# MM32F031x8 register map
Vendor: MindMotion Ltd.; Series: MM32F0; File version: 1.4
CPU: CM0 r0p0, little endian, no MPU, no FPU, 3 interrupt priority bits
Registers are 32-bit, read-write, reset 0x0 unless marked. A register's access mark holds for its fields unless they carry their own. Offsets are from the block's base; [hi:lo] are bit positions.

## RCC — Reset and clock control
Base 0x40021000
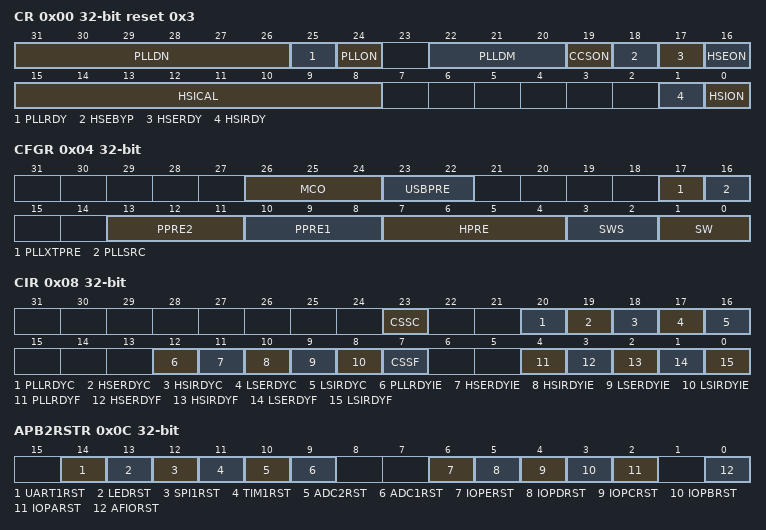
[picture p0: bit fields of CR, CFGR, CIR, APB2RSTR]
0x00 CR reset 0x3
  [31:26] PLLDN — PLL divider factor
  [25] PLLRDY — PLL clock ready flag
  [24] PLLON — PLL enable
  [22:20] PLLDM — PLL divider factor
  [19] CCSON — Clock security system enable
  [18] HSEBYP — External high-speed clock bypass
  [17] HSERDY — External high-speed clock ready flag
  [16] HSEON — External high-speed clock enable
  [15:8] HSICAL — Internal high-speed clock calibration
  [1] HSIRDY — Internal high-speed clock ready flag
  [0] HSION — Internal high-speed clock enable
0x04 CFGR
  [26:24] MCO — Microcontroller clock output
  [23:22] USBPRE — USB prescaler
  [17] PLLXTPRE — HSE divider for PLL entry
  [16] PLLSRC — PLL entry clock source
  [13:11] PPRE2 — APB high-speed prescaler(APB2)
  [10:8] PPRE1 — APB low-speed prescaler(APB1)
  [7:4] HPRE — AHB Prescaler
  [3:2] SWS — System clock switch status
  [1:0] SW — System clock switch
0x08 CIR
  [23] CSSC — Clock security system interrupt clear
  [20] PLLRDYC — PLL ready interrupt clear
  [19] HSERDYC — HSE ready interrupt clear
  [18] HSIRDYC — HSI ready interrupt clear
  [17] LSERDYC — LSE ready interrupt clear
  [16] LSIRDYC — LSI ready interrupt clear
  [12] PLLRDYIE — PLL ready interrupt enable
  [11] HSERDYIE — HSE ready interrupt enable
  [10] HSIRDYIE — HSI ready interrupt enable
  [9] LSERDYIE — LSE ready interrupt enable
  [8] LSIRDYIE — LSI ready interrupt enable
  [7] CSSF — Clock security system interrupt flag
  [4] PLLRDYF — PLL ready interrupt flag
  [3] HSERDYF — HSE ready interrupt flag
  [2] HSIRDYF — HSI ready interrupt flag
  [1] LSERDYF — LSE ready interrupt flag
  [0] LSIRDYF — LSI ready interrupt flag
0x0C APB2RSTR
  [14] UART1RST — UART 1 reset
  [13] LEDRST — LED reset
  [12] SPI1RST — SPI 1 reset
  [11] TIM1RST — TIM1 timer reset
  [10] ADC2RST — ADC2 interface reset
  [9] ADC1RST — ADC1 interface reset
  [6] IOPERST — IO port E reset
  [5] IOPDRST — IO port D reset
  [4] IOPCRST — IO port C reset
  [3] IOPBRST — IO port B reset
  [2] IOPARST — IO port A reset
  [0] AFIORST — Alternate function I/O reset
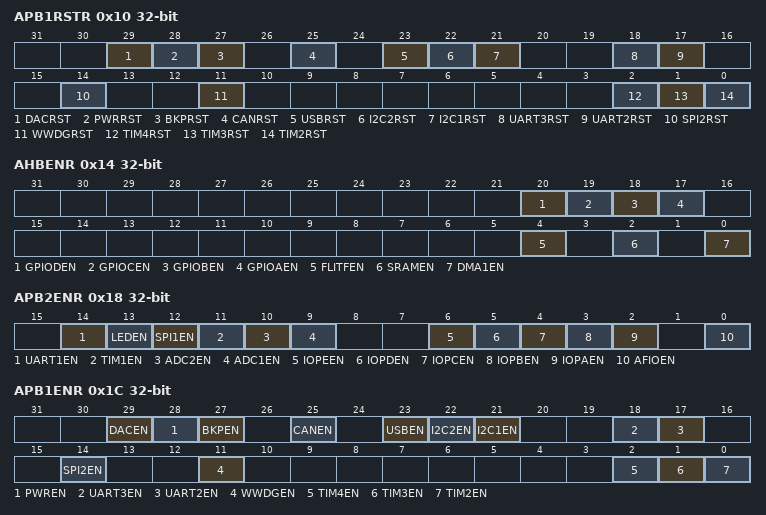
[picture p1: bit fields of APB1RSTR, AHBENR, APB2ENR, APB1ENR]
0x10 APB1RSTR
  [29] DACRST — DAC interface reset
  [28] PWRRST — Power interface reset
  [27] BKPRST — Backup interface reset
  [25] CANRST — CAN reset
  [23] USBRST — USB reset
  [22] I2C2RST — I2C 2 reset
  [21] I2C1RST — I2C 1 reset
  [18] UART3RST — UART 3 reset
  [17] UART2RST — UART 2 reset
  [14] SPI2RST — SPI 2 reset
  [11] WWDGRST — Window watchdog reset
  [2] TIM4RST — Timer 4 reset
  [1] TIM3RST — Timer 3 reset
  [0] TIM2RST — Timer 2 reset
0x14 AHBENR
  [20] GPIODEN — GPIOD clock enable
  [19] GPIOCEN — GPIOC clock enable
  [18] GPIOBEN — GPIOB clock enable
  [17] GPIOAEN — GPIOA clock enable
  [4] FLITFEN — FLITF clock enable
  [2] SRAMEN — SRAM interface clock enable
  [0] DMA1EN — DMA1 clock enable
0x18 APB2ENR
  [14] UART1EN — UART 1 clock enable
  [13] LEDEN — LED clock enable
  [12] SPI1EN — SPI 1 clock enable
  [11] TIM1EN — TIM1 Timer clock enable
  [10] ADC2EN — ADC 2 interface clock enable
  [9] ADC1EN — ADC 1 interface clock enable
  [6] IOPEEN — I/O port E clock enable
  [5] IOPDEN — I/O port D clock enable
  [4] IOPCEN — I/O port C clock enable
  [3] IOPBEN — I/O port B clock enable
  [2] IOPAEN — I/O port A clock enable
  [0] AFIOEN — Alternate function I/O clock enable
0x1C APB1ENR
  [29] DACEN — DAC interface clock enable
  [28] PWREN — Power interface clock enable
  [27] BKPEN — Backup interface clock enable
  [25] CANEN — CAN clock enable
  [23] USBEN — USB clock enable
  [22] I2C2EN — I2C 2 clock enable
  [21] I2C1EN — I2C 1 clock enable
  [18] UART3EN — UART 3 clock enable
  [17] UART2EN — UART 2 clock enable
  [14] SPI2EN — SPI 2 clock enable
  [11] WWDGEN — Window watchdog clock enable
  [2] TIM4EN — Timer 4 clock enable
  [1] TIM3EN — Timer 3 clock enable
  [0] TIM2EN — Timer 2 clock enable
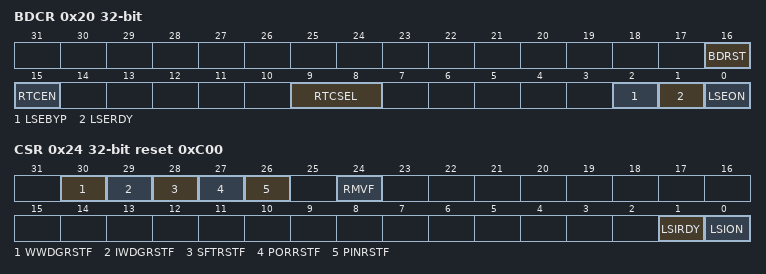
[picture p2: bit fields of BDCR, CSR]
0x20 BDCR
  [16] BDRST — Backup domain software reset
  [15] RTCEN — RTC clock enable
  [9:8] RTCSEL — RTC clock source selection
  [2] LSEBYP — External low-speed oscillator bypass
  [1] LSERDY — External low-speed oscillator ready
  [0] LSEON — External low-speed oscillator enable
0x24 CSR reset 0xC00
  [30] WWDGRSTF — Window watchdog reset flag
  [29] IWDGRSTF — Independent watchdog reset flag
  [28] SFTRSTF — Software reset flag
  [27] PORRSTF — POR/PDR reset flag
  [26] PINRSTF — PIN reset flag
  [24] RMVF — Remove reset flag
  [1] LSIRDY — Internal low-speed oscillator ready
  [0] LSION — Internal low-speed oscillator enable
